# MB9BF12xJ register map
File version: 1.0
Registers are 32-bit, read-write, reset 0x0 unless marked. A register's access mark holds for its fields unless they carry their own. Offsets are from the block's base; [hi:lo] are bit positions; {n}, {i} and the like mark numbered series.

## GPIO — peripheral GPIO
Base 0x40033000
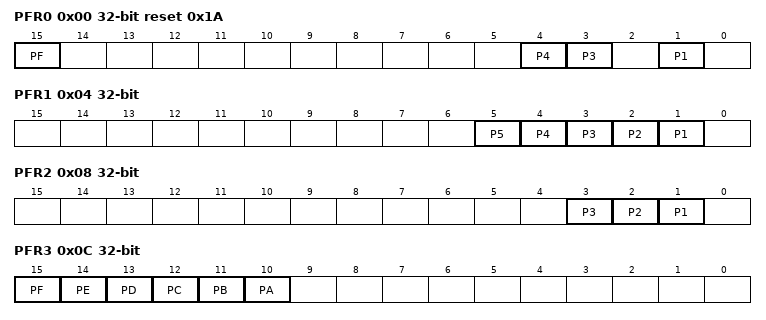
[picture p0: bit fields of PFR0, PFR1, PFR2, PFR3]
0x00 PFR0 reset 0x1A
  [15] PF, [4] P4, [3] P3, [1] P1
0x04 PFR1
  [n] P{n} (n=1..5)
0x08 PFR2
  [3] P3, [2] P2, [1] P1
0x0C PFR3
  [15] PF, [14] PE, [13] PD, [12] PC, [11] PB, [10] PA
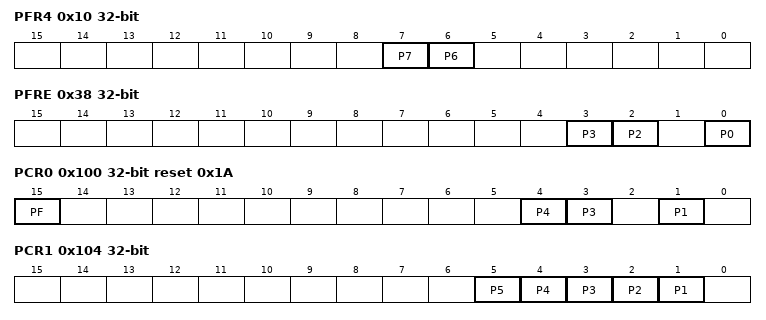
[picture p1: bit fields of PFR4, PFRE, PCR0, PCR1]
0x10 PFR4
  [7] P7, [6] P6
0x38 PFRE
  [3] P3, [2] P2, [0] P0
0x100 PCR0 reset 0x1A
  [15] PF, [4] P4, [3] P3, [1] P1
0x104 PCR1
  [n] P{n} (n=1..5)
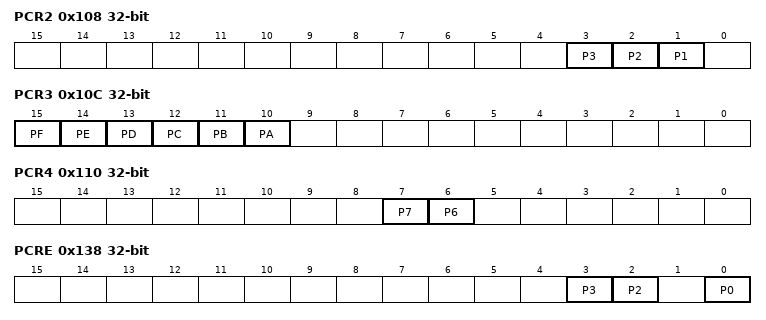
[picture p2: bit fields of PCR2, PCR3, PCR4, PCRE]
0x108 PCR2
  [3] P3, [2] P2, [1] P1
0x10C PCR3
  [15] PF, [14] PE, [13] PD, [12] PC, [11] PB, [10] PA
0x110 PCR4
  [7] P7, [6] P6
0x138 PCRE
  [3] P3, [2] P2, [0] P0
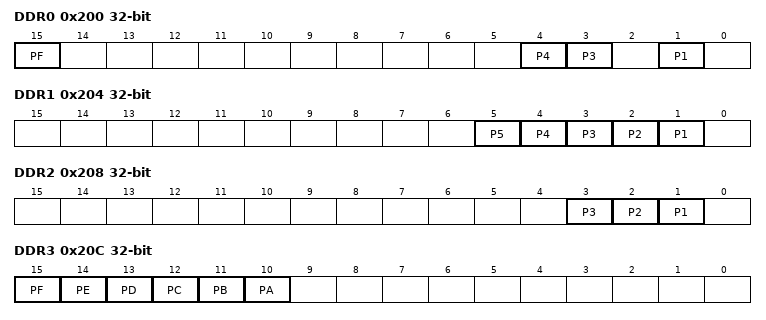
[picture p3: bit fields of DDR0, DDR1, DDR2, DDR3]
0x200 DDR0
  [15] PF, [4] P4, [3] P3, [1] P1
0x204 DDR1
  [n] P{n} (n=1..5)
0x208 DDR2
  [3] P3, [2] P2, [1] P1
0x20C DDR3
  [15] PF, [14] PE, [13] PD, [12] PC, [11] PB, [10] PA
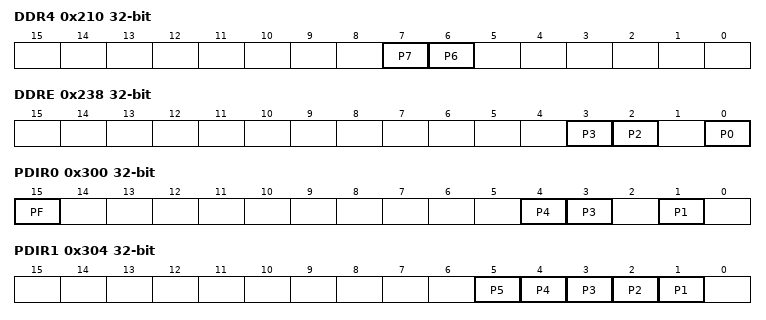
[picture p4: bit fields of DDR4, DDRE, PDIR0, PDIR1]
0x210 DDR4
  [7] P7, [6] P6
0x238 DDRE
  [3] P3, [2] P2, [0] P0
0x300 PDIR0
  [15] PF, [4] P4, [3] P3, [1] P1
0x304 PDIR1
  [n] P{n} (n=1..5)
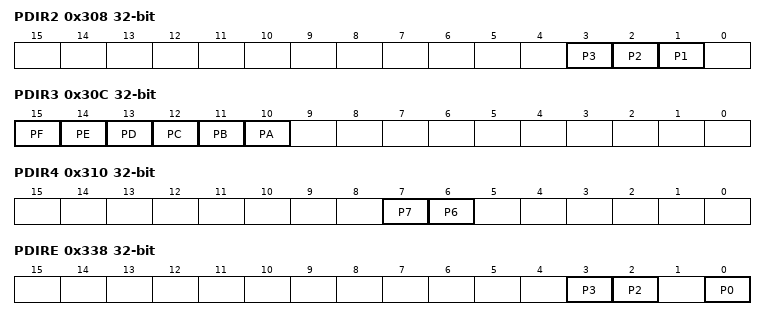
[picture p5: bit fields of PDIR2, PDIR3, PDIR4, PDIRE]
0x308 PDIR2
  [3] P3, [2] P2, [1] P1
0x30C PDIR3
  [15] PF, [14] PE, [13] PD, [12] PC, [11] PB, [10] PA
0x310 PDIR4
  [7] P7, [6] P6
0x338 PDIRE
  [3] P3, [2] P2, [0] P0
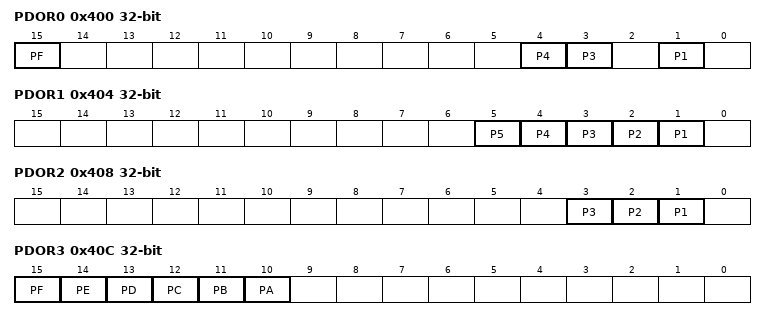
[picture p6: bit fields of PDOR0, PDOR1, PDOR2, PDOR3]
0x400 PDOR0
  [15] PF, [4] P4, [3] P3, [1] P1
0x404 PDOR1
  [n] P{n} (n=1..5)
0x408 PDOR2
  [3] P3, [2] P2, [1] P1
0x40C PDOR3
  [15] PF, [14] PE, [13] PD, [12] PC, [11] PB, [10] PA
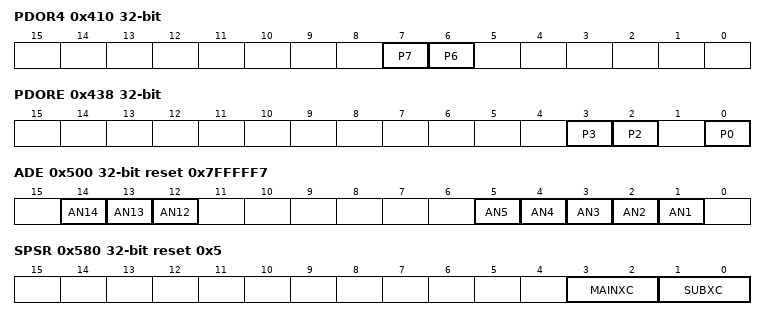
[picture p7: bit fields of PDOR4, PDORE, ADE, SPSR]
0x410 PDOR4
  [7] P7, [6] P6
0x438 PDORE
  [3] P3, [2] P2, [0] P0
0x500 ADE reset 0x7FFFFF7 (reset mask 0x7FFFFF7)
  [14] AN14, [13] AN13, [12] AN12, [n] AN{n} (n=1..5)
0x580 SPSR reset 0x5
  [3:2] MAINXC, [1:0] SUBXC
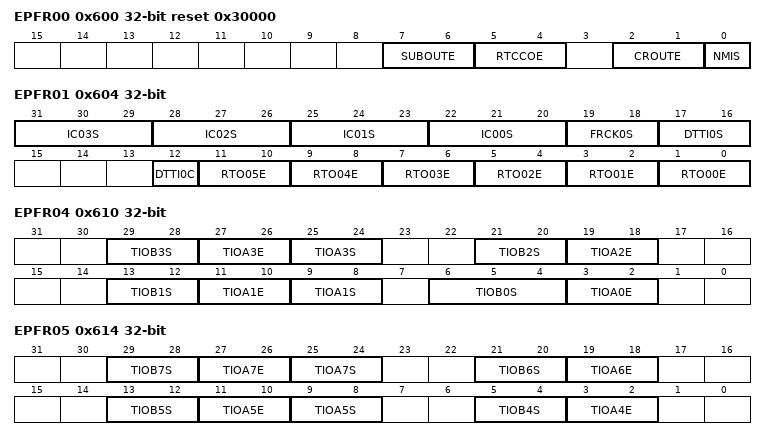
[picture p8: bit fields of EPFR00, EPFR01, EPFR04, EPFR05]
0x600 EPFR00 reset 0x30000
  [7:6] SUBOUTE, [5:4] RTCCOE, [2:1] CROUTE, [0] NMIS
0x604 EPFR01
  [3n+22:3n+20] IC{n:02}S (n=0..3), [19:18] FRCK0S, [17:16] DTTI0S, [12] DTTI0C, [2n+1:2n] RTO{n:02}E (n=0..5)
0x608 EPFR02 reset not defined
0x60C EPFR03 reset not defined
0x610 EPFR04
  [29:28] TIOB3S, [8n+3:8n+2] TIOA{n}E (n=0..3), [25:24] TIOA3S, [21:20] TIOB2S, [13:12] TIOB1S, [9:8] TIOA1S, [6:4] TIOB0S
0x614 EPFR05
  [8n-27:8n-28] TIOB{n}S (n=4..7), [8n-29:8n-30] TIOA{n}E (n=4..7), [25:24] TIOA7S, [9:8] TIOA5S
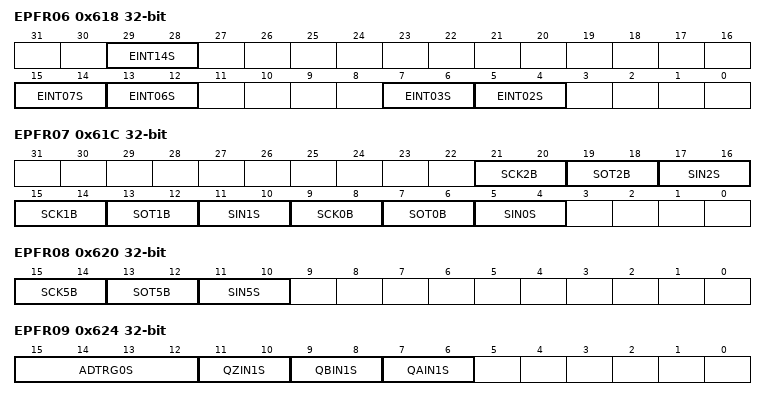
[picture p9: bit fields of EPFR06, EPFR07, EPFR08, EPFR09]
0x618 EPFR06
  [29:28] EINT14S, [15:14] EINT07S, [13:12] EINT06S, [7:6] EINT03S, [5:4] EINT02S
0x61C EPFR07
  [21:20] SCK2B, [19:18] SOT2B, [17:16] SIN2S, [15:14] SCK1B, [13:12] SOT1B, [11:10] SIN1S, [9:8] SCK0B, [7:6] SOT0B, [5:4] SIN0S
0x620 EPFR08
  [15:14] SCK5B, [13:12] SOT5B, [11:10] SIN5S
0x624 EPFR09
  [15:12] ADTRG0S, [11:10] QZIN1S, [9:8] QBIN1S, [7:6] QAIN1S
{0x600+4i} EPFR{i} reset not defined (i=10..14)
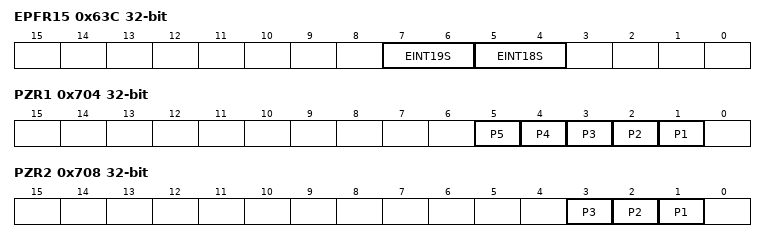
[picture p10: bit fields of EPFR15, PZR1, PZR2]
0x63C EPFR15
  [7:6] EINT19S, [5:4] EINT18S
{0x600+4i} EPFR{i} reset not defined (i=16..18)
0x704 PZR1
  [n] P{n} (n=1..5)
0x708 PZR2
  [3] P3, [2] P2, [1] P1

## LVD — peripheral LVD
Base 0x40035000
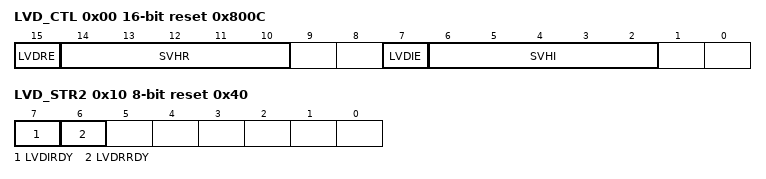
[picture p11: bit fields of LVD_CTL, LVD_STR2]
0x00 LVD_CTL 16-bit reset 0x800C
  [15] LVDRE, [14:10] SVHR, [7] LVDIE, [6:2] SVHI
0x04 LVD_STR 8-bit ro
  [7] LVDIR
0x08 LVD_CLR 8-bit reset 0x80
  [7] LVDCL
0x0C LVD_RLR reset 0x1
  [31:0] LVDLCK
0x10 LVD_STR2 8-bit ro reset 0x40
  [7] LVDIRDY, [6] LVDRRDY

## DS — peripheral DS
Base 0x40035100
0x00 REG_CTL 8-bit reset 0x4
  [2:1] ISUBSEL
0x04 RCK_CTL 8-bit reset 0x1
  [0] RTCCKE
0x700 PMD_CTL 8-bit
  [0] RTCE

## MFS0 — peripheral MFS0
Base 0x40038000
Same registers: MFS1 0x40038100, MFS2 0x40038200, MFS5 0x40038500
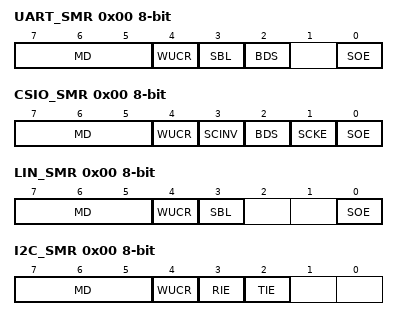
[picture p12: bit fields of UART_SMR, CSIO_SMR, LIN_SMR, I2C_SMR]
0x00 UART_SMR 8-bit (UART view)
  [7:5] MD, [4] WUCR, [3] SBL, [2] BDS, [0] SOE
0x00 CSIO_SMR 8-bit (CSIO view)
  [7:5] MD, [4] WUCR, [3] SCINV, [2] BDS, [1] SCKE, [0] SOE
0x00 LIN_SMR 8-bit (LIN view)
  [7:5] MD, [4] WUCR, [3] SBL, [0] SOE
0x00 I2C_SMR 8-bit (I2C view)
  [7:5] MD, [4] WUCR, [3] RIE, [2] TIE
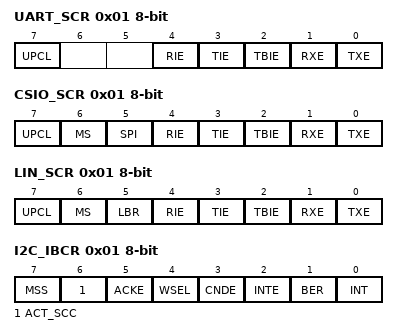
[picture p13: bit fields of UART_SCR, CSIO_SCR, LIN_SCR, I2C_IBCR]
0x01 UART_SCR 8-bit (UART view)
  [7] UPCL, [4] RIE, [3] TIE, [2] TBIE, [1] RXE, [0] TXE
0x01 CSIO_SCR 8-bit (CSIO view)
  [7] UPCL, [6] MS, [5] SPI, [4] RIE, [3] TIE, [2] TBIE, [1] RXE, [0] TXE
0x01 LIN_SCR 8-bit (LIN view)
  [7] UPCL, [6] MS, [5] LBR, [4] RIE, [3] TIE, [2] TBIE, [1] RXE, [0] TXE
0x01 I2C_IBCR 8-bit (I2C view)
  [7] MSS, [6] ACT_SCC, [5] ACKE, [4] WSEL, [3] CNDE, [2] INTE, [1] BER ro, [0] INT
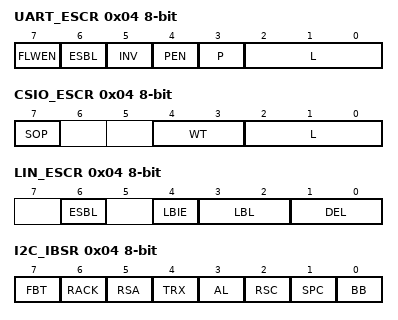
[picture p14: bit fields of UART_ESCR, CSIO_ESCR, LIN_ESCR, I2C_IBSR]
0x04 UART_ESCR 8-bit (UART view)
  [7] FLWEN, [6] ESBL, [5] INV, [4] PEN, [3] P, [2:0] L
0x04 CSIO_ESCR 8-bit (CSIO view)
  [7] SOP, [4:3] WT, [2:0] L
0x04 LIN_ESCR 8-bit (LIN view)
  [6] ESBL, [4] LBIE, [3:2] LBL, [1:0] DEL
0x04 I2C_IBSR 8-bit (I2C view)
  [7] FBT ro, [6] RACK ro, [5] RSA ro, [4] TRX ro, [3] AL ro, [2] RSC, [1] SPC, [0] BB ro
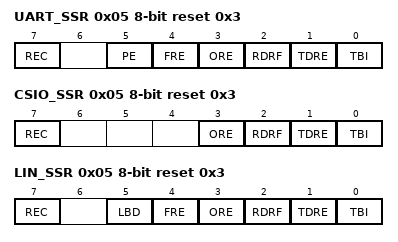
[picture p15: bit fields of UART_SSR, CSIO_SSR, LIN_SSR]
0x05 UART_SSR 8-bit reset 0x3 (UART view)
  [7] REC, [5] PE ro, [4] FRE ro, [3] ORE ro, [2] RDRF ro, [1] TDRE ro, [0] TBI ro
0x05 CSIO_SSR 8-bit reset 0x3 (CSIO view)
  [7] REC, [3] ORE ro, [2] RDRF ro, [1] TDRE ro, [0] TBI ro
0x05 LIN_SSR 8-bit reset 0x3 (LIN view)
  [7] REC, [5] LBD, [4] FRE ro, [3] ORE ro, [2] RDRF ro, [1] TDRE ro, [0] TBI ro
0x05 I2C_SSR 8-bit reset 0x3 (I2C view)
  [7] REC, [6] TSET, [5] DMA, [4] TBIE, [3] ORE ro, [2] RDRF ro, [1] TDRE ro, [0] TBI ro
0x08 UART_RDR 16-bit ro (reset mask 0x1FF) (UART view)
0x08 UART_TDR 16-bit wo reset 0x1FF (reset mask 0x1FF) (UART view)
0x08 CSIO_RDR 16-bit ro (reset mask 0x1FF) (CSIO view)
0x08 CSIO_TDR 16-bit wo reset 0x1FF (reset mask 0x1FF) (CSIO view)
0x08 LIN_RDR 16-bit ro (reset mask 0xFF) (LIN view)
0x08 LIN_TDR 16-bit wo reset 0xFF (reset mask 0xFF) (LIN view)
0x08 I2C_RDR 16-bit ro (reset mask 0xFF) (I2C view)
0x08 I2C_TDR 16-bit wo reset 0xFF (reset mask 0xFF) (I2C view)
0x0C UART_BGR 16-bit (UART view)
  [15] EXT, [14:8] BGR1, [7:0] BGR0
0x0C CSIO_BGR 16-bit (CSIO view)
  [14:8] BGR1, [7:0] BGR0
0x0C LIN_BGR 16-bit (LIN view)
  [15] EXT, [14:8] BGR1, [7:0] BGR0
0x0C I2C_BGR 16-bit (I2C view)
  [14:8] BGR1, [7:0] BGR0
0x10 I2C_ISBA 8-bit (I2C view)
  [7] SAEN, [6:0] SA
0x11 I2C_ISMK 8-bit reset 0x7F (I2C view)
  [7] EN, [6:0] SM
0x14 UART_FCR0 8-bit (UART view)
  [6] FLST ro, [5] FLD, [4] FSET, [3] FCL2, [2] FCL1, [1] FE2, [0] FE1
0x14 CSIO_FCR0 8-bit (CSIO view)
  [6] FLST ro, [5] FLD, [4] FSET, [3] FCL2, [2] FCL1, [1] FE2, [0] FE1
0x14 LIN_FCR0 8-bit (LIN view)
  [6] FLST ro, [5] FLD, [4] FSET, [3] FCL2, [2] FCL1, [1] FE2, [0] FE1
0x14 I2C_FCR0 8-bit (I2C view)
  [6] FLST ro, [5] FLD, [4] FSET, [3] FCL2, [2] FCL1, [1] FE2, [0] FE1
0x15 UART_FCR1 8-bit reset 0x4 (UART view)
  [4] FLSTE, [3] FRIIE, [2] FDRQ, [1] FTIE, [0] FSEL
0x15 CSIO_FCR1 8-bit reset 0x4 (CSIO view)
  [4] FLSTE, [3] FRIIE, [2] FDRQ, [1] FTIE, [0] FSEL
0x15 LIN_FCR1 8-bit reset 0x4 (LIN view)
  [4] FLSTE, [3] FRIIE, [2] FDRQ, [1] FTIE, [0] FSEL
0x15 I2C_FCR1 8-bit reset 0x4 (I2C view)
  [4] FLSTE, [3] FRIIE, [2] FDRQ, [1] FTIE, [0] FSEL
0x18 UART_FBYTE1 8-bit (UART view)
0x18 CSIO_FBYTE1 8-bit (CSIO view)
0x18 LIN_FBYTE1 8-bit (LIN view)
0x18 I2C_FBYTE1 8-bit (I2C view)
0x19 UART_FBYTE2 8-bit (UART view)
0x19 CSIO_FBYTE2 8-bit (CSIO view)
0x19 LIN_FBYTE2 8-bit (LIN view)
0x19 I2C_FBYTE2 8-bit (I2C view)
0x1D I2C_EIBCR 8-bit reset 0xC (I2C view)
  [5] SDAS, [4] SCLS, [3] SDAC, [2] SCLC, [1] SOCE, [0] BEC

## RTC — peripheral RTC
Base 0x4003B000
0x00 WTCR1
  [31] INTCRIE, [30] INTERIE, [29] INTALIE, [28] INTTMIE, [27] INTHIE, [26] INTMIE, [25] INTSIE, [24] INTSSIE, [23] INTCRI, [22] INTERI, [21] INTALI, [20] INTTMI, [19] INTHI, [18] INTMI, [17] INTSI, [16] INTSSI, [12] YEN, [11] MOEN, [10] DEN, [9] HEN, [8] MIEN, [6] BUSY ro, [5] SCRST, [4] SCST, [3] SRST, [2] RUN ro, [0] ST
0x04 WTCR2
  [10] TMRUN ro, [9] TMEN, [8] TMST, [0] CREAD
0x08 WTBR
  [n] BR{n} (n=0..23)
0x0C WTSR 8-bit
  [6:4] TS, [3:0] S
0x0D WTMIR 8-bit
  [6:4] TMI, [3:0] MI
0x0E WTHR 8-bit
  [5:4] TH, [3:0] H
0x0F WTDR 8-bit
  [5:4] TD, [3:0] D
0x10 WTDW 8-bit
  [2:0] DW
0x11 WTMOR 8-bit
  [4] TMO0, [3:0] MO
0x12 WTYR 8-bit
  [7:4] TY, [3:0] Y
0x15 ALMIR 8-bit
  [6:4] TAMI, [3:0] AMI
0x16 ALHR 8-bit
  [5:4] TAH, [3:0] AH
0x17 ALDR 8-bit
  [5:4] TAD, [3:0] AD
0x19 ALMOR 8-bit
  [4] TAMO0, [3:0] AMO
0x1A ALYR 8-bit
  [7:4] TAY, [3:0] AY
0x1C WTTR
  [n] TM{n} (n=0..17)
0x20 WTCLKS 8-bit
  [0] WTCLKS
0x21 WTCLKM 8-bit ro
  [1:0] WTCLKM
0x24 WTCAL 16-bit
  [9:0] WTCAL
0x26 WTCALEN 8-bit
  [0] WTCALEN
0x28 WTDIV 8-bit
  [3:0] WTDIV
0x29 WTDIVEN 8-bit
  [1] WTDIVRDY ro, [0] WTDIVEN
0x2C WTCALPRD 8-bit reset 0x13
  [5:0] WTCALPRD
0x30 WTCOSEL 8-bit
  [0] WTCOSEL

## DMAC — peripheral DMAC
Base 0x40060000
0x00 DMACR
  [31] DE, [30] DS, [28] PR, [27:24] DH
{0x10+0x10*i} DMACA{i} (i=0..3)
  [31] EB, [30] PB, [29] ST, [28:23] IS, [19:16] BC, [15:0] TC
{0x14+0x10*i} DMACB{i} (i=0..3)
  [29:28] MS, [27:26] TW, [25] FS, [24] FD, [23] RC, [22] RS, [21] RD, [20] EI, [19] CI, [18:16] SS, [0] EM
{0x18+0x10*i} DMACSA{i} (i=0..3)
{0x1C+0x10*i} DMACDA{i} (i=0..3)
